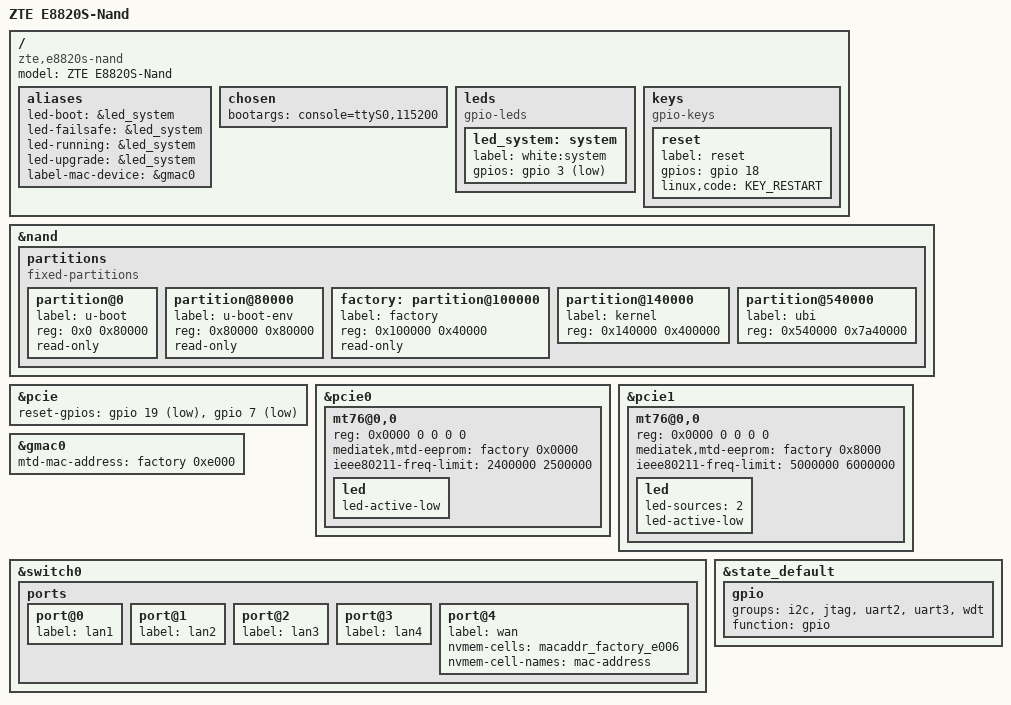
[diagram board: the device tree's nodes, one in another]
// SPDX-License-Identifier: GPL-2.0-or-later OR MIT

#include "mt7621.dtsi"

#include <dt-bindings/gpio/gpio.h>
#include <dt-bindings/input/input.h>

/ {
	compatible = "zte,e8820s-nand", "mediatek,mt7621-soc";
	model = "ZTE E8820S-Nand";

	aliases {
		led-boot = &led_system;
		led-failsafe = &led_system;
		led-running = &led_system;
		led-upgrade = &led_system;
		label-mac-device = &gmac0;
	};

	chosen {
		bootargs = "console=ttyS0,115200";
	};

	leds {
		compatible = "gpio-leds";
		led_system: system {
			label = "white:system";
			gpios = <&gpio 3 GPIO_ACTIVE_LOW>;
		};
	};

	keys {
		compatible = "gpio-keys";

		reset {
			label = "reset";
			gpios = <&gpio 18 GPIO_ACTIVE_HIGH>;
			linux,code = <KEY_RESTART>;
		};
	};
};

&nand {
	status = "okay";

	partitions {
		compatible = "fixed-partitions";
		#address-cells = <1>;
		#size-cells = <1>;

		partition@0 {
			label = "u-boot";
			reg = <0x0 0x80000>;
			read-only;
		};

		partition@80000 {
			label = "u-boot-env";
			reg = <0x80000 0x80000>;
			read-only;
		};

		factory: partition@100000 {
			label = "factory";
			reg = <0x100000 0x40000>;
			read-only;
		};

		partition@140000 {
			label = "kernel";
			reg = <0x140000 0x400000>;
		};

		partition@540000 {
			label = "ubi";
			reg = <0x540000 0x7a40000>;
		};
	};
};

&pcie {
	status = "okay";
	reset-gpios = <&gpio 19 GPIO_ACTIVE_LOW>,
		      <&gpio 7 GPIO_ACTIVE_LOW>;
};

&pcie0 {
	mt76@0,0 {
		reg = <0x0000 0 0 0 0>;
		mediatek,mtd-eeprom = <&factory 0x0000>;
		ieee80211-freq-limit = <2400000 2500000>;
		led {
			led-active-low;
		};
	};
};

&pcie1 {
	mt76@0,0 {
		reg = <0x0000 0 0 0 0>;
		mediatek,mtd-eeprom = <&factory 0x8000>;
		ieee80211-freq-limit = <5000000 6000000>;
		led {
			led-sources = <2>;
			led-active-low;
		};
	};
};

&gmac0 {
	mtd-mac-address = <&factory 0xe000>;
};

&switch0 {
	ports {
		port@0 {
			status = "okay";
			label = "lan1";
		};

		port@1 {
			status = "okay";
			label = "lan2";
		};

		port@2 {
			status = "okay";
			label = "lan3";
		};

		port@3 {
			status = "okay";
			label = "lan4";
		};

		port@4 {
			status = "okay";
			label = "wan";
			nvmem-cells = <&macaddr_factory_e006>;
			nvmem-cell-names = "mac-address";
		};
	};
};

&state_default {
	gpio {
		groups = "i2c", "jtag", "uart2", "uart3",  "wdt";
		function = "gpio";
	};
};
